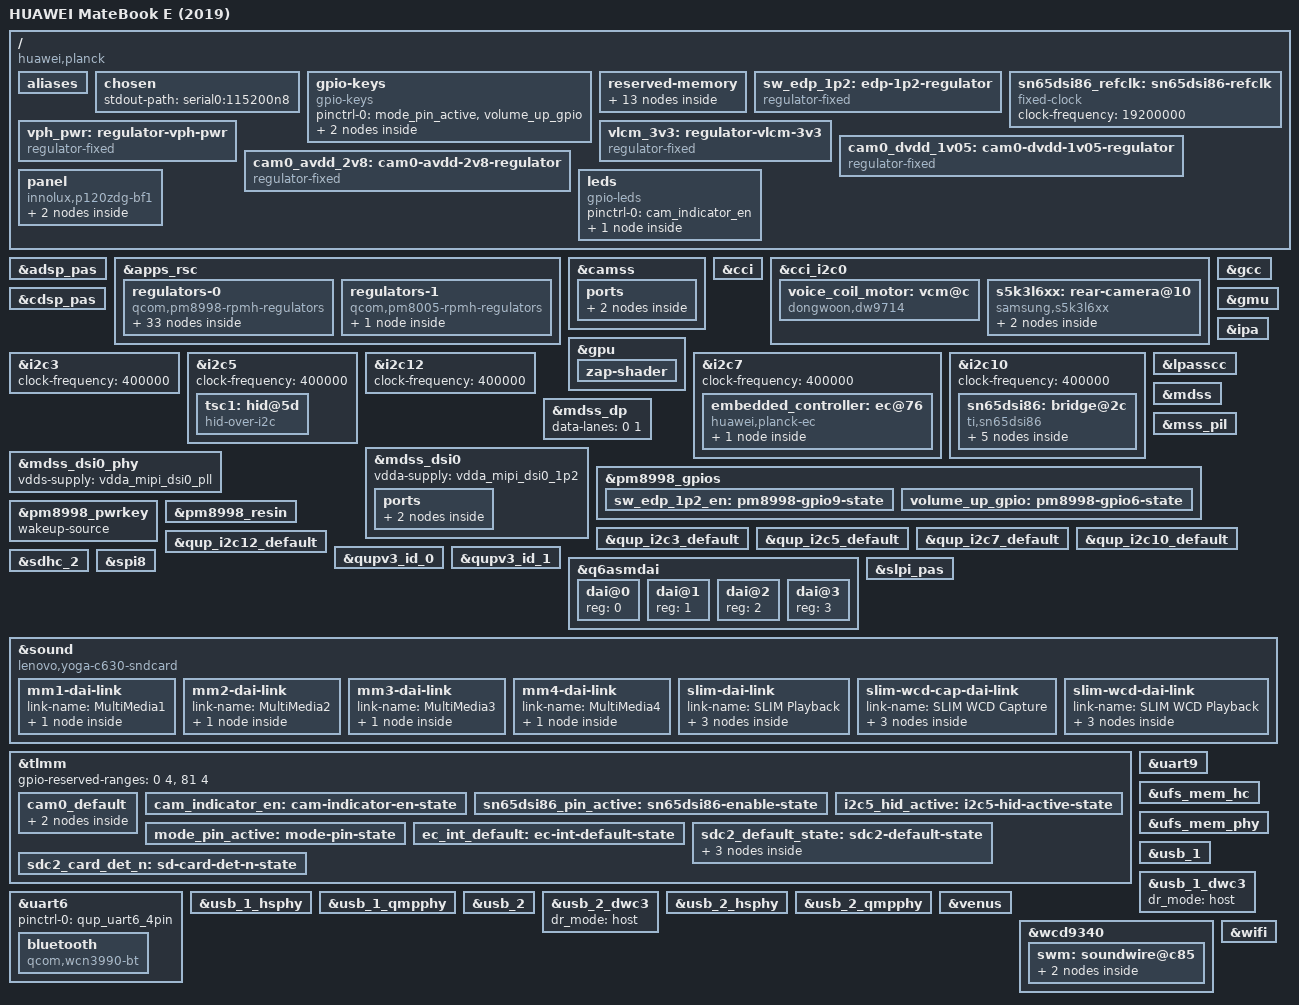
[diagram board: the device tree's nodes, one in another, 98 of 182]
// SPDX-License-Identifier: BSD-3-Clause
/*
 * HUAWEI MateBook E (2019)
 *
 * Copyright (c) 2024, NewWheat
 */

/dts-v1/;

#include <dt-bindings/leds/common.h>
#include <dt-bindings/pinctrl/qcom,pmic-gpio.h>
#include <dt-bindings/input/gpio-keys.h>
#include <dt-bindings/input/input.h>
#include <dt-bindings/regulator/qcom,rpmh-regulator.h>
#include <dt-bindings/sound/qcom,q6afe.h>
#include <dt-bindings/sound/qcom,q6asm.h>
#include "sdm850.dtsi"
#include "sdm845-wcd9340.dtsi"
#include "pm8998.dtsi"

/delete-node/ &rmtfs_mem;
/delete-node/ &qseecom_mem;
/delete-node/ &wlan_msa_mem;
/delete-node/ &slpi_mem;
/delete-node/ &ipa_fw_mem;
/delete-node/ &ipa_gsi_mem;
/delete-node/ &gpu_mem;
/delete-node/ &mpss_region;
/delete-node/ &adsp_mem;
/delete-node/ &cdsp_mem;
/delete-node/ &venus_mem;
/delete-node/ &mba_region;
/delete-node/ &spss_mem;
/delete-node/ &cont_splash_mem;

/ {
	model = "HUAWEI MateBook E (2019)";
	compatible = "huawei,planck", "qcom,sdm845";
	chassis-type = "convertible";

	aliases {
		serial0 = &uart9;
		serial1 = &uart6;
	};

	chosen {
		stdout-path = "serial0:115200n8";
	};

	gpio-keys {
		compatible = "gpio-keys";

		pinctrl-names = "default";
		pinctrl-0 = <&mode_pin_active &volume_up_gpio>;

		switch-mode {
			gpios = <&tlmm 79 GPIO_ACTIVE_HIGH>;
			linux,input-type = <EV_SW>;
			linux,code = <SW_TABLET_MODE>;
			wakeup-source;
		};

		key-vol-up {
			label = "Volume up";
			linux,code = <KEY_VOLUMEUP>;
			gpios = <&pm8998_gpios 6 GPIO_ACTIVE_LOW>;
			debounce-interval = <15>;
			wakeup-source;
		};
	};

	reserved-memory {
		rmtfs_mem: rmtfs-mem@99000000 {
			compatible = "qcom,rmtfs-mem";
			reg = <0 0x99000000 0 0x200000>;
			no-map;

			qcom,client-id = <1>;
			qcom,vmid = <15>;
		};

		cont_splash_mem: cont-splash-mem@80100000 {
			reg = <0x0 0x80100000 0x0 0xd00000>;
			no-map;
		};

		qseecom_mem: qseecom-mem@8b500000 {
			reg = <0 0x8b500000 0 0xa00000>;
			no-map;
		};

		wlan_msa_mem: wlan-msa-mem@8c400000 {
			reg = <0 0x8c400000 0 0x100000>;
			no-map;
		};

		slpi_mem: slpi-mem@8c500000 {
			reg = <0 0x8c500000 0 0x1200000>;
			no-map;
		};

		ipa_fw_mem: ipa-fw-mem@8d700000 {
			reg = <0 0x8d700000 0 0x100000>;
			no-map;
		};

		gpu_mem: gpu-mem@99200000 {
			reg = <0 0x99200000 0 0x5000>;
			no-map;
		};

		mpss_region: mpss-region@8e000000 {
			reg = <0 0x8e000000 0 0x8000000>;
			no-map;
		};

		adsp_mem: adsp-mem@96000000 {
			reg = <0 0x96000000 0 0x2000000>;
			no-map;
		};

		cdsp_mem: cdsp-mem@98000000 {
			reg = <0 0x98000000 0 0x800000>;
			no-map;
		};

		venus_mem: venus-mem@98800000 {
			reg = <0 0x98800000 0 0x500000>;
			no-map;
		};

		mba_region: mba-region@98d00000 {
			reg = <0 0x98d00000 0 0x200000>;
			no-map;
		};

		spss_mem: spss-mem@98f00000 {
			reg = <0 0x98f00000 0 0x100000>;
			no-map;
		};
	};

	sw_edp_1p2: edp-1p2-regulator {
		compatible = "regulator-fixed";
		regulator-name = "sw_edp_1p2";

		regulator-min-microvolt = <1200000>;
		regulator-max-microvolt = <1200000>;

		pinctrl-names = "default";
		pinctrl-0 = <&sw_edp_1p2_en>;

		gpio = <&pm8998_gpios 9 GPIO_ACTIVE_HIGH>;
		enable-active-high;

		vin-supply = <&vreg_l2a_1p2>;
	};

	sn65dsi86_refclk: sn65dsi86-refclk {
		compatible = "fixed-clock";
		#clock-cells = <0>;

		clock-frequency = <19200000>;
	};

	vph_pwr: regulator-vph-pwr {
		compatible = "regulator-fixed";
		regulator-name = "vph_pwr";

		regulator-min-microvolt = <3700000>;
		regulator-max-microvolt = <3700000>;

		regulator-always-on;
	};

	vlcm_3v3: regulator-vlcm-3v3 {
		compatible = "regulator-fixed";
		regulator-name = "vlcm_3v3";

		regulator-min-microvolt = <3300000>;
		regulator-max-microvolt = <3300000>;

		gpio = <&tlmm 88 GPIO_ACTIVE_HIGH>;
		enable-active-high;

		vin-supply = <&vph_pwr>;
	};

	cam0_dvdd_1v05: cam0-dvdd-1v05-regulator {
		compatible = "regulator-fixed";
		regulator-name = "cam0_dvdd_1v05";

		regulator-min-microvolt = <1050000>;
		regulator-max-microvolt = <1050000>;

		gpio = <&tlmm 61 GPIO_ACTIVE_HIGH>;

		enable-active-high;
		regulator-boot-on;
		//regulator-always-on;

		vin-supply = <&vreg_s4a_1p8>;
	};

	cam0_avdd_2v8: cam0-avdd-2v8-regulator {
		compatible = "regulator-fixed";
		regulator-name = "cam0_avdd_2v8";

		regulator-min-microvolt = <2800000>;
		regulator-max-microvolt = <2800000>;

		gpio = <&tlmm 63 GPIO_ACTIVE_HIGH>;

		enable-active-high;
		regulator-boot-on;
		//regulator-always-on;

		vin-supply = <&vph_pwr>;
	};

	panel: panel {
		compatible = "innolux,p120zdg-bf1";
		power-supply = <&vlcm_3v3>;
		no-hpd;

		port {
			panel_in_edp: endpoint {
				remote-endpoint = <&sn65dsi86_out>;
			};
		};
	};

	leds {
		compatible = "gpio-leds";

		pinctrl-names = "default";
		pinctrl-0 = <&cam_indicator_en>;

		led: camera_indicator_led {
			label = "white:camera-indicator";
			function = LED_FUNCTION_INDICATOR;
			color = <LED_COLOR_ID_WHITE>;
			gpios = <&tlmm 12 GPIO_ACTIVE_HIGH>;
			linux,default-trigger = "none";
			default-state = "off";
			/* Reuse as a panic indicator until we get a "camera on" trigger */
			panic-indicator;
		};
	};
};

&adsp_pas {
	firmware-name = "qcom/sdm850/HUAWEI/AL09/qcadsp850.mbn";
	status = "okay";
};

&apps_rsc {
	regulators-0 {
		compatible = "qcom,pm8998-rpmh-regulators";
		qcom,pmic-id = "a";

		vdd-s1-supply = <&vph_pwr>;
		vdd-s2-supply = <&vph_pwr>;
		vdd-s3-supply = <&vph_pwr>;
		vdd-s4-supply = <&vph_pwr>;
		vdd-s5-supply = <&vph_pwr>;
		vdd-s6-supply = <&vph_pwr>;
		vdd-s7-supply = <&vph_pwr>;
		vdd-s8-supply = <&vph_pwr>;
		vdd-s9-supply = <&vph_pwr>;
		vdd-s10-supply = <&vph_pwr>;
		vdd-s11-supply = <&vph_pwr>;
		vdd-s12-supply = <&vph_pwr>;
		vdd-s13-supply = <&vph_pwr>;
		vdd-l1-l27-supply = <&vreg_s7a_1p025>;
		vdd-l2-l8-l17-supply = <&vreg_s3a_1p35>;
		vdd-l3-l11-supply = <&vreg_s7a_1p025>;
		vdd-l4-l5-supply = <&vreg_s7a_1p025>;
		vdd-l6-supply = <&vph_pwr>;
		vdd-l7-l12-l14-l15-supply = <&vreg_s5a_2p04>;
		vdd-l26-supply = <&vreg_s3a_1p35>;
		vin-lvs-1-2-supply = <&vreg_s4a_1p8>;

		vreg_s2a_1p125: smps2 {
			regulator-min-microvolt = <1100000>;
			regulator-max-microvolt = <1100000>;
			regulator-initial-mode = <RPMH_REGULATOR_MODE_HPM>;
		};

		vreg_s3a_1p35: smps3 {
			regulator-min-microvolt = <1352000>;
			regulator-max-microvolt = <1352000>;
			regulator-initial-mode = <RPMH_REGULATOR_MODE_HPM>;
		};

		vreg_s4a_1p8: smps4 {
			regulator-min-microvolt = <1800000>;
			regulator-max-microvolt = <1800000>;
			regulator-initial-mode = <RPMH_REGULATOR_MODE_HPM>;
		};

		vreg_s5a_2p04: smps5 {
			regulator-min-microvolt = <1904000>;
			regulator-max-microvolt = <2040000>;
			regulator-initial-mode = <RPMH_REGULATOR_MODE_HPM>;
		};

		vreg_s7a_1p025: smps7 {
			regulator-min-microvolt = <900000>;
			regulator-max-microvolt = <1028000>;
			regulator-initial-mode = <RPMH_REGULATOR_MODE_HPM>;
		};

		vdd_qusb_hs0:
		vdda_hp_pcie_core:
		vdda_mipi_csi0_0p9:
		vdda_mipi_csi1_0p9:
		vdda_mipi_csi2_0p9:
		vdda_mipi_dsi0_pll:
		vdda_mipi_dsi1_pll:
		vdda_qlink_lv:
		vdda_qlink_lv_ck:
		vdda_qrefs_0p875:
		vdda_pcie_core:
		vdda_pll_cc_ebi01:
		vdda_pll_cc_ebi23:
		vdda_sp_sensor:
		vdda_ufs1_core:
		vdda_ufs2_core:
		vdda_usb1_ss_core:
		vdda_usb2_ss_core:
		vreg_l1a_0p875: ldo1 {
			regulator-min-microvolt = <880000>;
			regulator-max-microvolt = <880000>;
			regulator-initial-mode = <RPMH_REGULATOR_MODE_HPM>;
		};

		vddpx_10:
		vreg_l2a_1p2: ldo2 {
			regulator-min-microvolt = <1200000>;
			regulator-max-microvolt = <1200000>;
			regulator-initial-mode = <RPMH_REGULATOR_MODE_HPM>;
			regulator-always-on;
		};

		vreg_l3a_1p0: ldo3 {
			regulator-min-microvolt = <1000000>;
			regulator-max-microvolt = <1000000>;
			regulator-initial-mode = <RPMH_REGULATOR_MODE_HPM>;
		};

		vdd_wcss_cx:
		vdd_wcss_mx:
		vdda_wcss_pll:
		vreg_l5a_0p8: ldo5 {
			regulator-min-microvolt = <800000>;
			regulator-max-microvolt = <800000>;
			regulator-initial-mode = <RPMH_REGULATOR_MODE_HPM>;
		};

		vddpx_13:
		vreg_l6a_1p8: ldo6 {
			regulator-min-microvolt = <1856000>;
			regulator-max-microvolt = <1856000>;
			regulator-initial-mode = <RPMH_REGULATOR_MODE_HPM>;
		};

		vreg_l7a_1p8: ldo7 {
			regulator-min-microvolt = <1800000>;
			regulator-max-microvolt = <1800000>;
			regulator-initial-mode = <RPMH_REGULATOR_MODE_HPM>;
		};

		vreg_l8a_1p2: ldo8 {
			regulator-min-microvolt = <1200000>;
			regulator-max-microvolt = <1248000>;
			regulator-initial-mode = <RPMH_REGULATOR_MODE_HPM>;
		};

		vreg_l9a_1p8: ldo9 {
			regulator-min-microvolt = <1704000>;
			regulator-max-microvolt = <2928000>;
			regulator-initial-mode = <RPMH_REGULATOR_MODE_HPM>;
		};

		vreg_l10a_1p8: ldo10 {
			regulator-min-microvolt = <1704000>;
			regulator-max-microvolt = <2928000>;
			regulator-initial-mode = <RPMH_REGULATOR_MODE_HPM>;
		};

		vreg_l11a_1p0: ldo11 {
			regulator-min-microvolt = <1000000>;
			regulator-max-microvolt = <1048000>;
			regulator-initial-mode = <RPMH_REGULATOR_MODE_HPM>;
		};

		vdd_qfprom:
		vdd_qfprom_sp:
		vdda_apc1_cs_1p8:
		vdda_gfx_cs_1p8:
		vdda_qrefs_1p8:
		vdda_qusb_hs0_1p8:
		vddpx_11:
		vreg_l12a_1p8: ldo12 {
			regulator-min-microvolt = <1800000>;
			regulator-max-microvolt = <1800000>;
			regulator-initial-mode = <RPMH_REGULATOR_MODE_HPM>;
		};

		vddpx_2:
		vreg_l13a_2p95: ldo13 {
			regulator-min-microvolt = <1800000>;
			regulator-max-microvolt = <2960000>;
			regulator-initial-mode = <RPMH_REGULATOR_MODE_HPM>;
		};

		vreg_l14a_1p88: ldo14 {
			regulator-min-microvolt = <1800000>;
			regulator-max-microvolt = <1800000>;
			regulator-initial-mode = <RPMH_REGULATOR_MODE_HPM>;
			regulator-always-on;
		};

		vreg_l15a_1p8: ldo15 {
			regulator-min-microvolt = <1800000>;
			regulator-max-microvolt = <1800000>;
			regulator-initial-mode = <RPMH_REGULATOR_MODE_HPM>;
		};

		vreg_l16a_2p7: ldo16 {
			regulator-min-microvolt = <2704000>;
			regulator-max-microvolt = <2704000>;
			regulator-initial-mode = <RPMH_REGULATOR_MODE_HPM>;
		};

		vreg_l17a_1p3: ldo17 {
			regulator-min-microvolt = <1304000>;
			regulator-max-microvolt = <1304000>;
			regulator-initial-mode = <RPMH_REGULATOR_MODE_HPM>;
		};

		vreg_l18a_2p7: ldo18 {
			regulator-min-microvolt = <2704000>;
			regulator-max-microvolt = <2960000>;
			regulator-initial-mode = <RPMH_REGULATOR_MODE_HPM>;
		};

		vreg_l19a_3p0: ldo19 {
			regulator-min-microvolt = <2856000>;
			regulator-max-microvolt = <3104000>;
			regulator-initial-mode = <RPMH_REGULATOR_MODE_HPM>;
		};

		vreg_l20a_2p95: ldo20 {
			regulator-min-microvolt = <2704000>;
			regulator-max-microvolt = <2960000>;
			regulator-initial-mode = <RPMH_REGULATOR_MODE_HPM>;
		};

		vreg_l21a_2p95: ldo21 {
			regulator-min-microvolt = <2704000>;
			regulator-max-microvolt = <2960000>;
			regulator-initial-mode = <RPMH_REGULATOR_MODE_HPM>;
		};

		vreg_l22a_2p85: ldo22 {
			regulator-min-microvolt = <2864000>;
			regulator-max-microvolt = <3312000>;
			regulator-initial-mode = <RPMH_REGULATOR_MODE_HPM>;

			regulator-boot-on;
		};

		vreg_l23a_3p3: ldo23 {
			regulator-min-microvolt = <3000000>;
			regulator-max-microvolt = <3312000>;
			regulator-initial-mode = <RPMH_REGULATOR_MODE_HPM>;
		};

		vdda_qusb_hs0_3p1:
		vreg_l24a_3p075: ldo24 {
			regulator-min-microvolt = <3088000>;
			regulator-max-microvolt = <3088000>;
			regulator-initial-mode = <RPMH_REGULATOR_MODE_HPM>;
		};

		vreg_l25a_3p3: ldo25 {
			regulator-min-microvolt = <3300000>;
			regulator-max-microvolt = <3312000>;
			regulator-initial-mode = <RPMH_REGULATOR_MODE_HPM>;
		};

		vdda_hp_pcie_1p2:
		vdda_hv_ebi0:
		vdda_hv_ebi1:
		vdda_hv_ebi2:
		vdda_hv_ebi3:
		vdda_mipi_csi_1p25:
		vdda_mipi_dsi0_1p2:
		vdda_mipi_dsi1_1p2:
		vdda_pcie_1p2:
		vdda_ufs1_1p2:
		vdda_ufs2_1p2:
		vdda_usb1_ss_1p2:
		vdda_usb2_ss_1p2:
		vreg_l26a_1p2: ldo26 {
			regulator-min-microvolt = <1200000>;
			regulator-max-microvolt = <1200000>;
			regulator-initial-mode = <RPMH_REGULATOR_MODE_HPM>;
		};

		vreg_l28a_3p0: ldo28 {
			regulator-min-microvolt = <2856000>;
			regulator-max-microvolt = <3008000>;
			regulator-initial-mode = <RPMH_REGULATOR_MODE_HPM>;
		};

		vreg_lvs1a_1p8: lvs1 {
			regulator-min-microvolt = <1800000>;
			regulator-max-microvolt = <1800000>;
			
			//enable-active-high;
			regulator-boot-on;
			regulator-always-on;
		};

		vreg_lvs2a_1p8: lvs2 {
			regulator-min-microvolt = <1800000>;
			regulator-max-microvolt = <1800000>;
		};
	};

	regulators-1 {
		compatible = "qcom,pm8005-rpmh-regulators";
		qcom,pmic-id = "c";

		vdd-s1-supply = <&vph_pwr>;
		vdd-s2-supply = <&vph_pwr>;
		vdd-s3-supply = <&vph_pwr>;
		vdd-s4-supply = <&vph_pwr>;

		vreg_s2c_0p752: smps2 {
			regulator-min-microvolt = <752000>;
			regulator-max-microvolt = <752000>;
		};
	};
};

&camss {
	status = "okay";

	vdda-phy-supply = <&vdda_mipi_csi0_0p9>;
	vdda-pll-supply = <&vdda_mipi_csi_1p25>;

	ports {
		#address-cells = <1>;
		#size-cells = <0>;
		port@0 {
			reg = <0>;
			csiphy0_ep: endpoint {
				data-lanes = <0 1 2 3>;
				remote-endpoint = <&s5k3l6xx_ep>;
			};
		};
	};
};

&cci {
	status = "okay";
};
/*
/ {
    fake-reg-mclk0 {
        compatible = "regulator-fixed-clock";
        regulator-name = "fake-reg-mclk0";
        pinctrl-names = "default";
        pinctrl-0 = <&cam_mclk0_default>;
        clocks = <&clock_camcc CAM_CC_MCLK0_CLK>;
        regulator-always-on;
    };
	fake-reg-mclk1 {
        compatible = "regulator-fixed-clock";
        regulator-name = "fake-reg-mclk1";
        pinctrl-names = "default";
        pinctrl-0 = <&cam_mclk1_default>;
        clocks = <&clock_camcc CAM_CC_MCLK1_CLK>;
        regulator-always-on;
    };
};

&tlmm {
    cam_mclk0_default: cam-mclk0-default {
        pins = "gpio13";
        function = "cam_mclk";
        drive-strength = <2>;
        bias-disable;
    };
	cam_mclk1_default: cam-mclk1-default {
        pins = "gpio15";
        function = "cam_mclk";
        drive-strength = <2>;
        bias-disable;
    };
};
*/

&cci_i2c0 {
	voice_coil_motor: vcm@c {
		compatible = "dongwoon,dw9714";
		reg = <0x0c>;
		vcc-supply = <&vreg_lvs1a_1p8>;
	};

	s5k3l6xx: rear-camera@10 {
		status = "okay";
		compatible = "samsung,s5k3l6xx";
		reg = <0x10>;

		clocks = <&clock_camcc CAM_CC_MCLK0_CLK>;
		clock-names = "mclk";
		clock-frequency = <24000000>;

		pinctrl-names = "default";
		pinctrl-0 = <&cam0_default>;

		rstn-gpios = <&tlmm 23 GPIO_ACTIVE_LOW>;

		ldo-supply = <&vreg_l22a_2p85>;
		vdda-supply = <&cam0_avdd_2v8>;		//analog power 2.8V
		vddd-supply = <&cam0_dvdd_1v05>;	//VDDD digital power 1.2V, camera expects 0.95V-1.15V
		vddio-supply = <&vreg_lvs1a_1p8>;	//I/O power supply 1.8V

		power-domains = <&clock_camcc TITAN_TOP_GDSC>;

		lens-focus = <&voice_coil_motor>;
		orientation = <1>;
		rotation = <0>;

		port {
			s5k3l6xx_ep: endpoint {
				data-lanes = <1 2 3 4>;
				remote-endpoint = <&csiphy0_ep>;
			};
		};
	};
};

&cdsp_pas {
	firmware-name = "qcom/sdm850/HUAWEI/AL09/qccdsp850.mbn";
	status = "okay";
};

&gcc {
	protected-clocks = <GCC_QSPI_CORE_CLK>,
			   <GCC_QSPI_CORE_CLK_SRC>,
			   <GCC_QSPI_CNOC_PERIPH_AHB_CLK>,
			   <GCC_LPASS_Q6_AXI_CLK>,
			   <GCC_LPASS_SWAY_CLK>;
};

&gmu {
	status = "okay";
};

&gpu {
	status = "okay";
	zap-shader {
		memory-region = <&gpu_mem>;
		firmware-name = "qcom/sdm850/HUAWEI/AL09/qcdxkmsuc850.mbn";
	};
};

&i2c3 {
	status = "okay";
	clock-frequency = <400000>;
};

&i2c5 {
	status = "okay";
	clock-frequency = <400000>;

	tsc1: hid@5d {
		compatible = "hid-over-i2c";
		reg = <0x5d>;
		hid-descr-addr = <0x1>;

		interrupts-extended = <&tlmm 125 IRQ_TYPE_LEVEL_LOW>;
		wakeup-source;

		pinctrl-names = "default";
		pinctrl-0 = <&i2c5_hid_active>;
	};
};

&i2c7 {
	status = "okay";
	clock-frequency = <400000>;

	embedded_controller: ec@76 {
		compatible = "huawei,planck-ec";
		reg = <0x76>;

		interrupts-extended = <&tlmm 24 IRQ_TYPE_LEVEL_LOW>;
		wakeup-source;

		pinctrl-names = "default";
		pinctrl-0 = <&ec_int_default>;

		connector {
			compatible = "usb-c-connector";

			/*
			ports {
				#address-cells = <1>;
				#size-cells = <0>;
				port@1 {
					reg = <1>;
					planck_ec_dp_in: endpoint {
						remote-endpoint = <&mdss_dp_out>;
					};
				};
			};
			*/
		};
	};
};

&i2c10 {
	status = "okay";
	clock-frequency = <400000>;

	sn65dsi86: bridge@2c {
		compatible = "ti,sn65dsi86";
		reg = <0x2c>;

		pinctrl-names = "default";
		pinctrl-0 = <&sn65dsi86_pin_active>;

		enable-gpios = <&tlmm 96 GPIO_ACTIVE_HIGH>;

		vcca-supply = <&sw_edp_1p2>;
		vcc-supply = <&sw_edp_1p2>;
		vpll-supply = <&vreg_l14a_1p88>;
		vccio-supply = <&vreg_l14a_1p88>;

		clocks = <&sn65dsi86_refclk>;
		clock-names = "refclk";

		no-hpd;

		ports {
			#address-cells = <1>;
			#size-cells = <0>;

			port@0 {
				reg = <0>;
				sn65dsi86_in: endpoint {
					remote-endpoint = <&mdss_dsi0_out>;
				};
			};

			port@1 {
				reg = <1>;
				sn65dsi86_out: endpoint {
					remote-endpoint = <&panel_in_edp>;
				};
			};
		};
	};
};

&i2c12 {
	status = "okay";
	clock-frequency = <400000>;
};

&ipa {
	status = "okay";
	qcom,gsi-loader = "self";
	memory-region = <&ipa_fw_mem>;
	firmware-name = "qcom/sdm850/HUAWEI/AL09/ipa_fws.elf";
};

&lpasscc {
	status = "okay";
};

&mdss {
	status = "okay";
};

&mdss_dp {
	status = "okay";
	data-lanes = <0 1>;

	/*
	ports {
		port@1 {
			reg = <1>;
			mdss_dp_out: endpoint {
				remote-endpoint = <&planck_ec_dp_in>;
			};
		};
	};
	*/
};

&mdss_dsi0 {
	status = "okay";
	vdda-supply = <&vdda_mipi_dsi0_1p2>;

	ports {
		port@1 {
			endpoint {
				remote-endpoint = <&sn65dsi86_in>;
				data-lanes = <0 1 2 3>;
			};
		};
	};
};

&mdss_dsi0_phy {
	status = "okay";
	vdds-supply = <&vdda_mipi_dsi0_pll>;
};

&mss_pil {
	status = "okay";
	firmware-name = "qcom/sdm850/HUAWEI/AL09/qcdsp1v2850.mbn", "qcom/sdm850/HUAWEI/AL09/qcdsp2850.mbn";
};

&pm8998_gpios {
	sw_edp_1p2_en: pm8998-gpio9-state {
		pins = "gpio9";
		function = "normal";
		
		bias-disable;
		qcom,drive-strength = <PMIC_GPIO_STRENGTH_NO>;
	};

	volume_up_gpio: pm8998-gpio6-state {
		pins = "gpio6";
		function = "normal";
		
		input-enable;
		bias-pull-up;
		qcom,drive-strength = <PMIC_GPIO_STRENGTH_NO>;
	};
};

&pm8998_pwrkey {
	status = "okay";
	wakeup-source;
};

&pm8998_resin {
	linux,code = <KEY_VOLUMEDOWN>;
	status = "okay";
	wakeup-source;
};

&qup_i2c3_default {
	drive-strength = <2>;
	bias-disable;
};

&qup_i2c5_default {
	drive-strength = <2>;
	bias-disable;
};

&qup_i2c7_default {
	drive-strength = <2>;
	bias-disable;
};

&qup_i2c10_default {
	drive-strength = <2>;
	bias-disable;
};

&qup_i2c12_default {
	drive-strength = <2>;
	bias-disable;
};

&qupv3_id_0 {
	status = "okay";
};

&qupv3_id_1 {
	status = "okay";
};

&q6asmdai {
	dai@0 {
		reg = <0>;
	};

	dai@1 {
		reg = <1>;
	};

	dai@2 {
		reg = <2>;
	};

	dai@3 {
		reg = <3>;
	};
};

&sdhc_2 {
	status = "okay";

	pinctrl-names = "default";
	pinctrl-0 = <&sdc2_default_state &sdc2_card_det_n>;

	vmmc-supply = <&vreg_l21a_2p95>;
	vqmmc-supply = <&vddpx_2>;

	bus-width = <4>;
	cd-gpios = <&tlmm 126 GPIO_ACTIVE_HIGH>;
};

&slpi_pas {
	firmware-name = "qcom/sdm850/HUAWEI/AL09/qcslpi850.mbn";
	status = "okay";
};

&spi8 {
	status = "okay";
};

&sound {
	compatible = "lenovo,yoga-c630-sndcard", "qcom,sdm845-sndcard";
	model = "HUAWEI-PAK_AL09-M1040";

	status = "okay";

	audio-routing =
		"RX_BIAS", "MCLK",
		"AMIC2", "MIC BIAS2",
		"DMIC2", "MIC BIAS3", /* Digital Mic4 */
		"DMIC1", "MIC BIAS1", /* Digital Mic5 */
		"SpkrLeft IN", "SPK1 OUT",
		"SpkrRight IN", "SPK2 OUT";

	mm1-dai-link {
		link-name = "MultiMedia1";
		cpu {
			sound-dai = <&q6asmdai MSM_FRONTEND_DAI_MULTIMEDIA1>;
		};
	};

	mm2-dai-link {
		link-name = "MultiMedia2";
		cpu {
			sound-dai = <&q6asmdai MSM_FRONTEND_DAI_MULTIMEDIA2>;
		};
	};

	mm3-dai-link {
		link-name = "MultiMedia3";
		cpu {
			sound-dai = <&q6asmdai MSM_FRONTEND_DAI_MULTIMEDIA3>;
		};
	};

	mm4-dai-link {
		link-name = "MultiMedia4";
		cpu {
			sound-dai = <&q6asmdai MSM_FRONTEND_DAI_MULTIMEDIA4>;
		};
	};

	slim-dai-link {
		link-name = "SLIM Playback";
		cpu {
			sound-dai = <&q6afedai SLIMBUS_0_RX>;
		};

		platform {
			sound-dai = <&q6routing>;
		};

		codec {
			sound-dai = <&left_spkr>, <&right_spkr>, <&swm 0>, <&wcd9340 0>;
		};
	};

	slim-wcd-cap-dai-link {
		link-name = "SLIM WCD Capture";
		cpu {
			sound-dai = <&q6afedai SLIMBUS_0_TX>;
		};

		platform {
			sound-dai = <&q6routing>;
		};

		codec {
			sound-dai = <&wcd9340 1>;
		};
	};

	slim-wcd-dai-link {
		link-name = "SLIM WCD Playback";
		cpu {
			sound-dai = <&q6afedai SLIMBUS_1_RX>;
		};

		platform {
			sound-dai = <&q6routing>;
		};

		codec {
			sound-dai = <&wcd9340 2>;
		};
	};
};

&tlmm {
	gpio-reserved-ranges = <0 4>, <81 4>;

	cam0_default: cam0_default {
		rst {
			pins = "gpio23";
			function = "gpio";

			drive-strength = <2>;
			bias-disable;
		};

		mclk0 {
			pins = "gpio13";
			function = "cam_mclk";

			drive-strength = <2>;
			bias-disable;
		};
	};

	cam_indicator_en: cam-indicator-en-state {
		pins = "gpio12";
		function = "gpio";

		drive-strength = <2>;
		bias-disable;
	};

	sn65dsi86_pin_active: sn65dsi86-enable-state {
		pins = "gpio96";
		function = "gpio";

		drive-strength = <2>;
		bias-disable;
	};

	i2c5_hid_active: i2c5-hid-active-state {
		pins = "gpio125";
		function = "gpio";

		input-enable;
		bias-pull-up;
		drive-strength = <2>;
	};

	mode_pin_active: mode-pin-state {
		pins = "gpio79";
		function = "gpio";

		bias-disable;
	};

	ec_int_default: ec-int-default-state {
		pins = "gpio24";
		function = "gpio";
		
		drive-strength = <2>;
		bias-disable;
	};

	sdc2_default_state: sdc2-default-state {
		clk-pins {
			pins = "sdc2_clk";
			bias-disable;
			drive-strength = <16>;
		};

		cmd-pins {
			pins = "sdc2_cmd";
			bias-pull-up;
			drive-strength = <16>;
		};

		data-pins {
			pins = "sdc2_data";
			bias-pull-up;
			drive-strength = <16>;
		};
	};

	sdc2_card_det_n: sd-card-det-n-state {
		pins = "gpio126";
		function = "gpio";
		bias-pull-up;
	};
};

&uart6 {
	pinctrl-names = "default";
	pinctrl-0 = <&qup_uart6_4pin>;
	status = "okay";

	bluetooth {
		compatible = "qcom,wcn3990-bt";

		vddio-supply = <&vreg_s4a_1p8>;
		vddxo-supply = <&vreg_l7a_1p8>;
		vddrf-supply = <&vreg_l17a_1p3>;
		vddch0-supply = <&vreg_l25a_3p3>;
		vddch1-supply = <&vreg_l23a_3p3>;
		max-speed = <3200000>;
	};
};

&uart9 {
	status = "okay";
};

&ufs_mem_hc {
	status = "okay";

	reset-gpios = <&tlmm 150 GPIO_ACTIVE_LOW>;

	vcc-supply = <&vreg_l20a_2p95>;
	vcc-max-microamp = <600000>;
};

&ufs_mem_phy {
	status = "okay";

	vdda-phy-supply = <&vdda_ufs1_core>;
	vdda-pll-supply = <&vdda_ufs1_1p2>;
};

&usb_1 {
	status = "okay";
};

&usb_1_dwc3 {
	dr_mode = "host";
};

&usb_1_hsphy {
	status = "okay";

	vdd-supply = <&vdda_usb1_ss_core>;
	vdda-pll-supply = <&vdda_qusb_hs0_1p8>;
	vdda-phy-dpdm-supply = <&vdda_qusb_hs0_3p1>;

	qcom,imp-res-offset-value = <8>;
	qcom,hstx-trim-value = <QUSB2_V2_HSTX_TRIM_21_6_MA>;
	qcom,preemphasis-level = <QUSB2_V2_PREEMPHASIS_5_PERCENT>;
	qcom,preemphasis-width = <QUSB2_V2_PREEMPHASIS_WIDTH_HALF_BIT>;
};

&usb_1_qmpphy {
	status = "okay";

	vdda-phy-supply = <&vdda_usb1_ss_1p2>;
	vdda-pll-supply = <&vdda_usb1_ss_core>;
};

&usb_2 {
	status = "okay";
};

&usb_2_dwc3 {
	dr_mode = "host";
};

&usb_2_hsphy {
	status = "okay";

	vdd-supply = <&vdda_usb2_ss_core>;
	vdda-pll-supply = <&vdda_qusb_hs0_1p8>;
	vdda-phy-dpdm-supply = <&vdda_qusb_hs0_3p1>;

	qcom,imp-res-offset-value = <8>;
	qcom,hstx-trim-value = <QUSB2_V2_HSTX_TRIM_22_8_MA>;
};

&usb_2_qmpphy {
	status = "okay";

	vdda-phy-supply = <&vdda_usb2_ss_1p2>;
	vdda-pll-supply = <&vdda_usb2_ss_core>;
};

&venus {
	status = "okay";
	firmware-name = "qcom/sdm850/HUAWEI/AL09/qcvss850.mbn";
};

&wcd9340 {
	reset-gpios = <&tlmm 64 GPIO_ACTIVE_HIGH>;
	vdd-buck-supply = <&vreg_s4a_1p8>;
	vdd-buck-sido-supply = <&vreg_s4a_1p8>;
	vdd-tx-supply = <&vreg_s4a_1p8>;
	vdd-rx-supply = <&vreg_s4a_1p8>;
	vdd-io-supply = <&vreg_s4a_1p8>;
	qcom,mbhc-buttons-vthreshold-microvolt = <75000 150000 237000 500000 500000 500000 500000 500000>;
	qcom,mbhc-headset-vthreshold-microvolt = <1700000>;
	qcom,mbhc-headphone-vthreshold-microvolt = <50000>;
	qcom,micbias1-microvolt = <1800000>;
	qcom,micbias2-microvolt = <2700000>;
	qcom,micbias3-microvolt = <1800000>;

	swm: soundwire@c85 {
		left_spkr: speaker@0,3 {
			compatible = "sdw10217211000";
			reg = <0 3>;
			powerdown-gpios = <&wcdgpio 1 GPIO_ACTIVE_LOW>;
			#thermal-sensor-cells = <0>;
			sound-name-prefix = "SpkrLeft";
			#sound-dai-cells = <0>;
		};

		right_spkr: speaker@0,4 {
			compatible = "sdw10217211000";
			reg = <0 4>;
			powerdown-gpios = <&wcdgpio 2 GPIO_ACTIVE_LOW>;
			#thermal-sensor-cells = <0>;
			sound-name-prefix = "SpkrRight";
			#sound-dai-cells = <0>;
		};
	};
};

&wifi {
	status = "okay";

	vdd-0.8-cx-mx-supply = <&vreg_l5a_0p8>;
	vdd-1.8-xo-supply = <&vreg_l7a_1p8>;
	vdd-1.3-rfa-supply = <&vreg_l17a_1p3>;
	vdd-3.3-ch0-supply = <&vreg_l25a_3p3>;
	vdd-3.3-ch1-supply = <&vreg_l23a_3p3>;

	qcom,snoc-host-cap-8bit-quirk;
	qcom,ath10k-calibration-variant = "Lenovo_C630";
};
